# AM13E23019 register map
Vendor: Texas Instruments; File version: 1.0
CPU: CM33 r0p1, little endian, MPU, FPU, VTOR, 4 interrupt priority bits
Registers are 32-bit, read-write, reset 0x0 unless marked. A register's access mark holds for its fields unless they carry their own. Offsets are from the block's base; [hi:lo] are bit positions; lines under a group give offsets from that group; {n}, {i} and the like mark numbered series.

## ADC0 — ADC module
Base 0x40000000
Same registers: ADC1 0x40002000, ADC2 0x40004000
0x800 GPRCM group
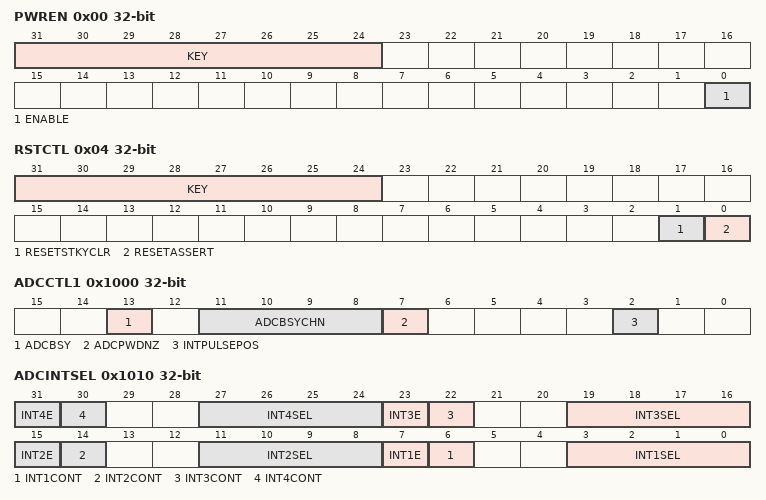
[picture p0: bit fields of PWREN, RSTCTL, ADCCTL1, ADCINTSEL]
  0x00 PWREN access per field — Power enable
    [31:24] KEY wo — Key which must be written for the write to take effect.
      38=KEY (Write key.)
    [0] ENABLE rw — Power Enable
      0=DISABLE (Disable Power.); 1=ENABLE (Enable Power.)
  0x04 RSTCTL access per field — Reset Control.
    [31:24] KEY wo — Key which must be written for the write to take effect.
      177=KEY (Write key.)
    [1] RESETSTKYCLR rw — Reset sticky bit clear.
      0=NOP (Writing 0 has no effect.); 1=CLR (Clear reset sticky bit.)
    [0] RESETASSERT rw — Reset assertion to the peripheral.
      0=NOP (Writing 0 has no effect.); 1=ASSERT (Assert reset.)
  0x14 STAT ro — Status Register
    [16] RESETSTKYCLR — Reset sticky bit
      0=NORES (The peripheral has not been reset since this bit was last cleared by RESETSTKYCLR in the RSTCTL register.); 1=RESET (The peripheral was reset since the last bit clear.)
0x1000 ADCCTL1 access per field — ADC Control 1 Register
  [13] ADCBSY ro — ADC Busy
  [11:8] ADCBSYCHN ro — ADC Busy Channel
  [7] ADCPWDNZ rw — ADC Power Down
  [2] INTPULSEPOS rw — ADC Interrupt Pulse Position.
0x1004 ADCCTL2 — ADC Control 2 Register
  [3:0] PRESCALE — ADC Clock Prescaler
0x1010 ADCINTSEL — ADC Interrupt 1, 2, 3 and 4 Selection Register
  [8n-1] INT{n}E (n=1..4) — ADCINT{n} Interrupt Enable
  [8n-2] INT{n}CONT (n=1..4) — ADCINT{n} Continue to Interrupt Mode
  [8n-5:8n-8] INT{n}SEL (n=1..4) — ADCINT{n} EOC Source Select
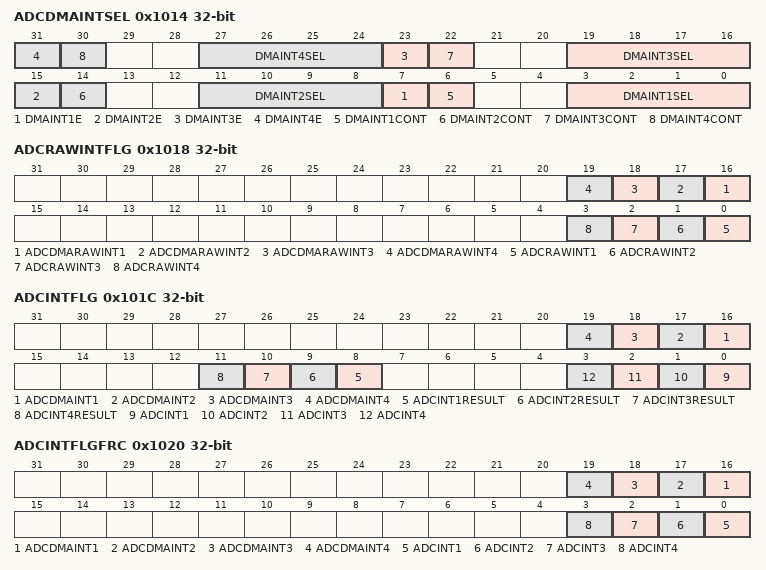
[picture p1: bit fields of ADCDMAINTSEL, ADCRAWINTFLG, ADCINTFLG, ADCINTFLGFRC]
0x1014 ADCDMAINTSEL — ADC DMA Interrupt 1, 2, 3 and 4 Selection Register
  [8n-1] DMAINT{n}E (n=1..4) — ADCDMAINT{n} Interrupt Enable
  [8n-2] DMAINT{n}CONT (n=1..4) — ADCDMAINT{n} Continue to Interrupt Mode
  [8n-5:8n-8] DMAINT{n}SEL (n=1..4) — ADCDMAINT{n} EOC Source Select
0x1018 ADCRAWINTFLG ro — ADC Raw Interrupt Flag Register
  [n+15] ADCDMARAWINT{n} (n=1..4) — ADC DMA Raw Interrupt {n} Flag
  [n-1] ADCRAWINT{n} (n=1..4) — ADC Raw Interrupt {n} Flag
0x101C ADCINTFLG ro — ADC Interrupt Flag Register
  [n+15] ADCDMAINT{n} (n=1..4) — ADC DMA Interrupt {n} Flag
  [n+7] ADCINT{n}RESULT (n=1..4) — ADC Interrupt {n} Results Ready
  [n-1] ADCINT{n} (n=1..4) — ADC Interrupt {n} Flag
0x1020 ADCINTFLGFRC — ADC Interrupt Flag Force Register
  [n+15] ADCDMAINT{n} (n=1..4) — ADC DMA Interrupt {n} Flag Force
  [n-1] ADCINT{n} (n=1..4) — ADC Interrupt {n} Flag Force
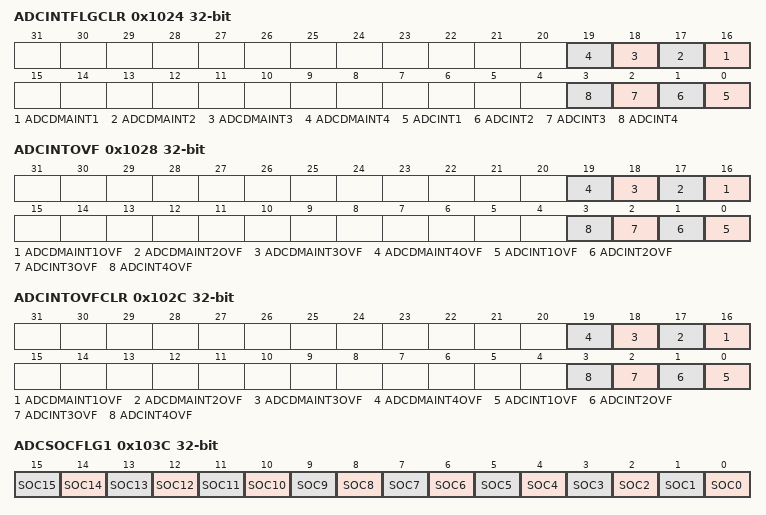
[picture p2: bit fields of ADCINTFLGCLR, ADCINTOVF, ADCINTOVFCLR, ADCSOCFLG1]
0x1024 ADCINTFLGCLR — ADC Interrupt Flag Clear Register
  [n+15] ADCDMAINT{n} (n=1..4) — ADC DMA Interrupt {n} Flag Clear
  [n-1] ADCINT{n} (n=1..4) — ADC Interrupt {n} Flag Clear
0x1028 ADCINTOVF ro — ADC Interrupt Overflow Register
  [n+15] ADCDMAINT{n}OVF (n=1..4) — ADC DMA Interrupt {n} Overflow Flags
  [n-1] ADCINT{n}OVF (n=1..4) — ADC Interrupt {n} Overflow Flags
0x102C ADCINTOVFCLR — ADC Interrupt Overflow Clear Register
  [n+15] ADCDMAINT{n}OVF (n=1..4) — ADC DMA Interrupt {n} Overflow Clear Bits
  [n-1] ADCINT{n}OVF (n=1..4) — ADC Interrupt {n} Overflow Clear Bits
0x103C ADCSOCFLG1 ro — ADC SOC Flag 1 Register
  [n] SOC{n} (n=0..15) — SOC{n} Start of Conversion Flag
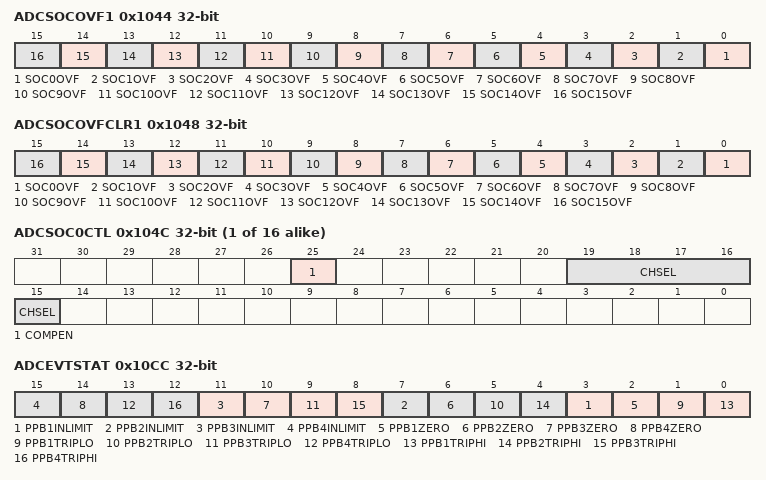
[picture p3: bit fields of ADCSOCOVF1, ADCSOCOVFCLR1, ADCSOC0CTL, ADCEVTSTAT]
0x1044 ADCSOCOVF1 ro — ADC SOC Overflow 1 Register
  [n] SOC{n}OVF (n=0..15) — SOC{n} Start of Conversion Overflow Flag
0x1048 ADCSOCOVFCLR1 — ADC SOC Overflow Clear 1 Register
  [n] SOC{n}OVF (n=0..15) — SOC{n} Clear Start of Conversion Overflow Bit
{0x104C+4i} ADCSOC{i}CTL (i=0..15) — ADC SOC{i} Control Register
  [25] COMPEN — SOC{i} Threshold comparator enable
  [19:15] CHSEL — SOC{i} Channel Select
0x10CC ADCEVTSTAT ro — ADC Event Status Register
  [4n-1] PPB{n}INLIMIT (n=1..4) — Post Processing Block {n} Within trip limit Flag
  [4n-2] PPB{n}ZERO (n=1..4) — Post Processing Block {n} Zero Crossing Flag
  [4n-3] PPB{n}TRIPLO (n=1..4) — Post Processing Block {n} Trip Low Flag
  [4n-4] PPB{n}TRIPHI (n=1..4) — Post Processing Block {n} Trip High Flag
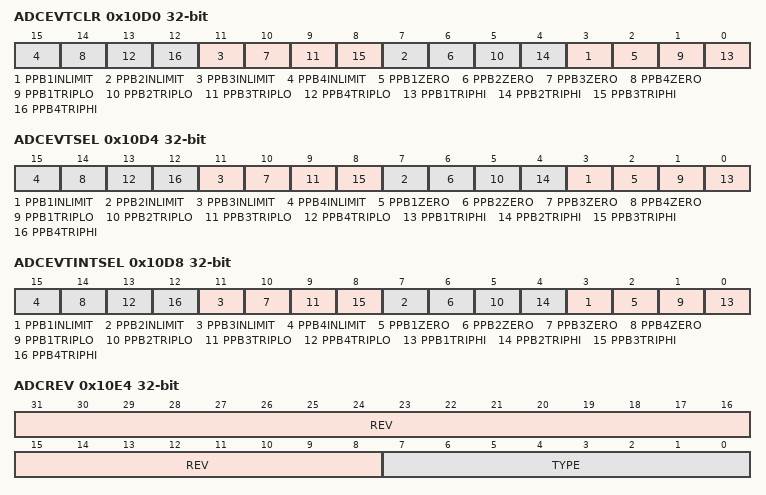
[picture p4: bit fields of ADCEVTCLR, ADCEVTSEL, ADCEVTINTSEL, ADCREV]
0x10D0 ADCEVTCLR — ADC Event Clear Register
  [4n-1] PPB{n}INLIMIT (n=1..4) — Post Processing Block {n} Within trip limit flag Clear
  [4n-2] PPB{n}ZERO (n=1..4) — Post Processing Block {n} Zero Crossing Clear
  [4n-3] PPB{n}TRIPLO (n=1..4) — Post Processing Block {n} Trip Low Clear
  [4n-4] PPB{n}TRIPHI (n=1..4) — Post Processing Block {n} Trip High Clear
0x10D4 ADCEVTSEL — ADC Event Selection Register
  [4n-1] PPB{n}INLIMIT (n=1..4) — Post Processing Block {n} Within trip limit event enable
  [4n-2] PPB{n}ZERO (n=1..4) — Post Processing Block {n} Zero Crossing Event Enable
  [4n-3] PPB{n}TRIPLO (n=1..4) — Post Processing Block {n} Trip Low Event Enable
  [4n-4] PPB{n}TRIPHI (n=1..4) — Post Processing Block {n} Trip High Event Enable
0x10D8 ADCEVTINTSEL — ADC Event Interrupt Selection Register
  [4n-1] PPB{n}INLIMIT (n=1..4) — Post Processing Block {n} Within trip limit Interrupt enable
  [4n-2] PPB{n}ZERO (n=1..4) — Post Processing Block {n} Zero Crossing Interrupt Enable
  [4n-3] PPB{n}TRIPLO (n=1..4) — Post Processing Block {n} Trip Low Interrupt Enable
  [4n-4] PPB{n}TRIPHI (n=1..4) — Post Processing Block {n} Trip High Interrupt Enable
0x10E4 ADCREV ro — ADC Revision Register
  [31:8] REV — ADC Revision
  [7:0] TYPE — ADC Type
0x10E8 ADCOFFTRIM — ADC Offset Trim Register 1
  [7:0] OFFTRIM — ADC Offset Trim
{0x10E0+0x20*i} ADCPPB{i}CONFIG (i=1..4)
  [5] CBCEN — Cycle By Cycle Enable
{0x10F0+0x20*i} ADCPPB{i}TRIPHI (i=1..4) — ADC PPB{i} Trip High Register
  [15:0] LIMITHI — ADC Post Processing Block {i} Trip High Limit
{0x10F4+0x20*i} ADCPPB{i}TRIPLO (i=1..4) — ADC PPB{i} Trip Low/Trigger Time Stamp Register
  [15:0] LIMITLO — ADC Post Processing Block {i} Trip Low Limit
0x1180 ADCINTCYCLE — ADC Early Interrupt Generation Cycle
  [5:0] DELAY — Delay from ADCSOC fall edge to early Interrupt generation.
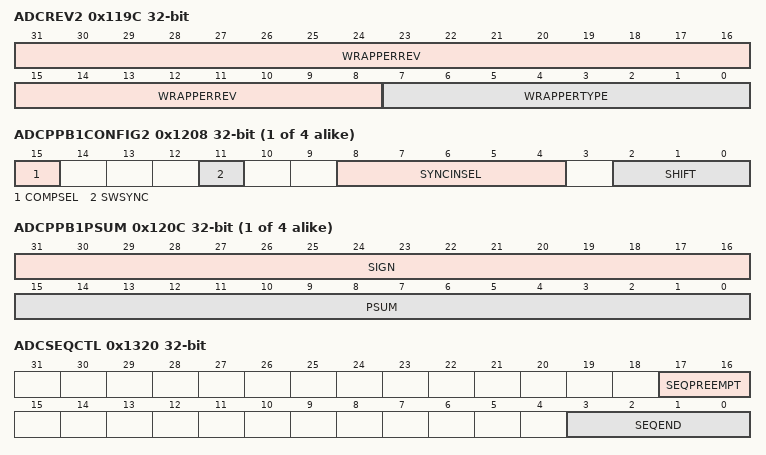
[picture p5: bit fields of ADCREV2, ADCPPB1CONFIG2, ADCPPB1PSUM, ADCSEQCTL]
0x119C ADCREV2 ro — ADC Wrapper Revision Register
  [31:8] WRAPPERREV — ADC Wrapper Revision
  [7:0] WRAPPERTYPE — ADC Wrapper Type
{0x11C0+0x40*i} ADCPPB{i}LIMIT (i=1..4) — ADC PPB{i}Conversion Count Limit Register
  [1:0] LIMIT — Post Processing Block {i} Limit
{0x11C4+0x40*i} ADCPPB{i}PCOUNT ro (i=1..4) — ADC PPB{i} Partial Conversion Count Register
  [2:0] PCOUNT — Post Processing Block {i} Partial Count
{0x11C8+0x40*i} ADCPPB{i}CONFIG2 (i=1..4) — ADC PPB{i} Sum Shift Register
  [15] COMPSEL — Post Processing Block {i} Compare Source Select
  [11] SWSYNC — Post Processing Block {i} Software Force Sync.
  [8:4] SYNCINSEL — Post Processing Block {i} Sync. Input Select
  [2:0] SHIFT — Post Processing Block {i} Right Shift
{0x11CC+0x40*i} ADCPPB{i}PSUM ro (i=1..4) — ADC PPB{i} Partial Sum Register
  [31:16] SIGN — Sign Extended Bits
  [15:0] PSUM — Post Processing Block {i} Oversampling Partial Sum
0x1320 ADCSEQCTL — ADC Sequencer common control Register
  [17:16] SEQPREEMPT — SOC Sequnece Preempt and restart setting
  [3:0] SEQEND — END SOC of SEQ4
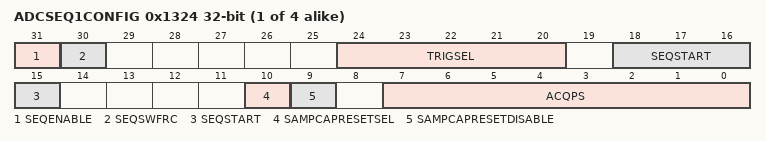
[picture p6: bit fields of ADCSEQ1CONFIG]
{0x1320+4i} ADCSEQ{i}CONFIG (i=1..4) — ADC Sequencer {i} Config register
  [31] SEQENABLE — SEQ{i}Enable
  [30] SEQSWFRC — SEQ{i} Software Force
  [24:20] TRIGSEL — SEQ{i} Trigger Source Select
  [18:15] SEQSTART — Beginning SOC of SEQ{i}
  [10] SAMPCAPRESETSEL — SEQ{i} Sample Cap Reset Select
  [9] SAMPCAPRESETDISABLE — SEQ{i} Sample Cap Reset Enable
  [7:0] ACQPS — SEQ{i} Acquisition Prescale
